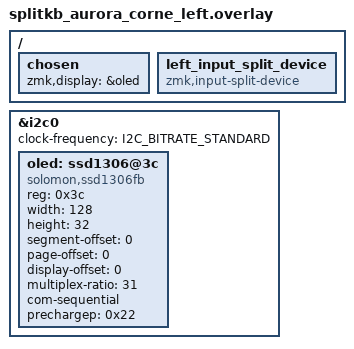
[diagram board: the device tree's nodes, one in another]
/*
 * Copyright (c) 2022 The ZMK Contributors
 *
 * SPDX-License-Identifier: MIT
 */

#include <dt-bindings/zmk/matrix_transform.h>

/ {
    chosen {
        zmk,display = &oled;
    };
    
    /* Add input split device for receiving trackball data from right half */
    left_input_split_device {
        compatible = "zmk,input-split-device";
    };
};

&i2c0 {
    status = "okay";
    clock-frequency = <I2C_BITRATE_STANDARD>;
    
    oled: ssd1306@3c {
        compatible = "solomon,ssd1306fb";
        reg = <0x3c>;
        width = <128>;
        height = <32>;
        segment-offset = <0>;
        page-offset = <0>;
        display-offset = <0>;
        multiplex-ratio = <31>;
        com-sequential;
        prechargep = <0x22>;
        status = "okay";
    };
};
